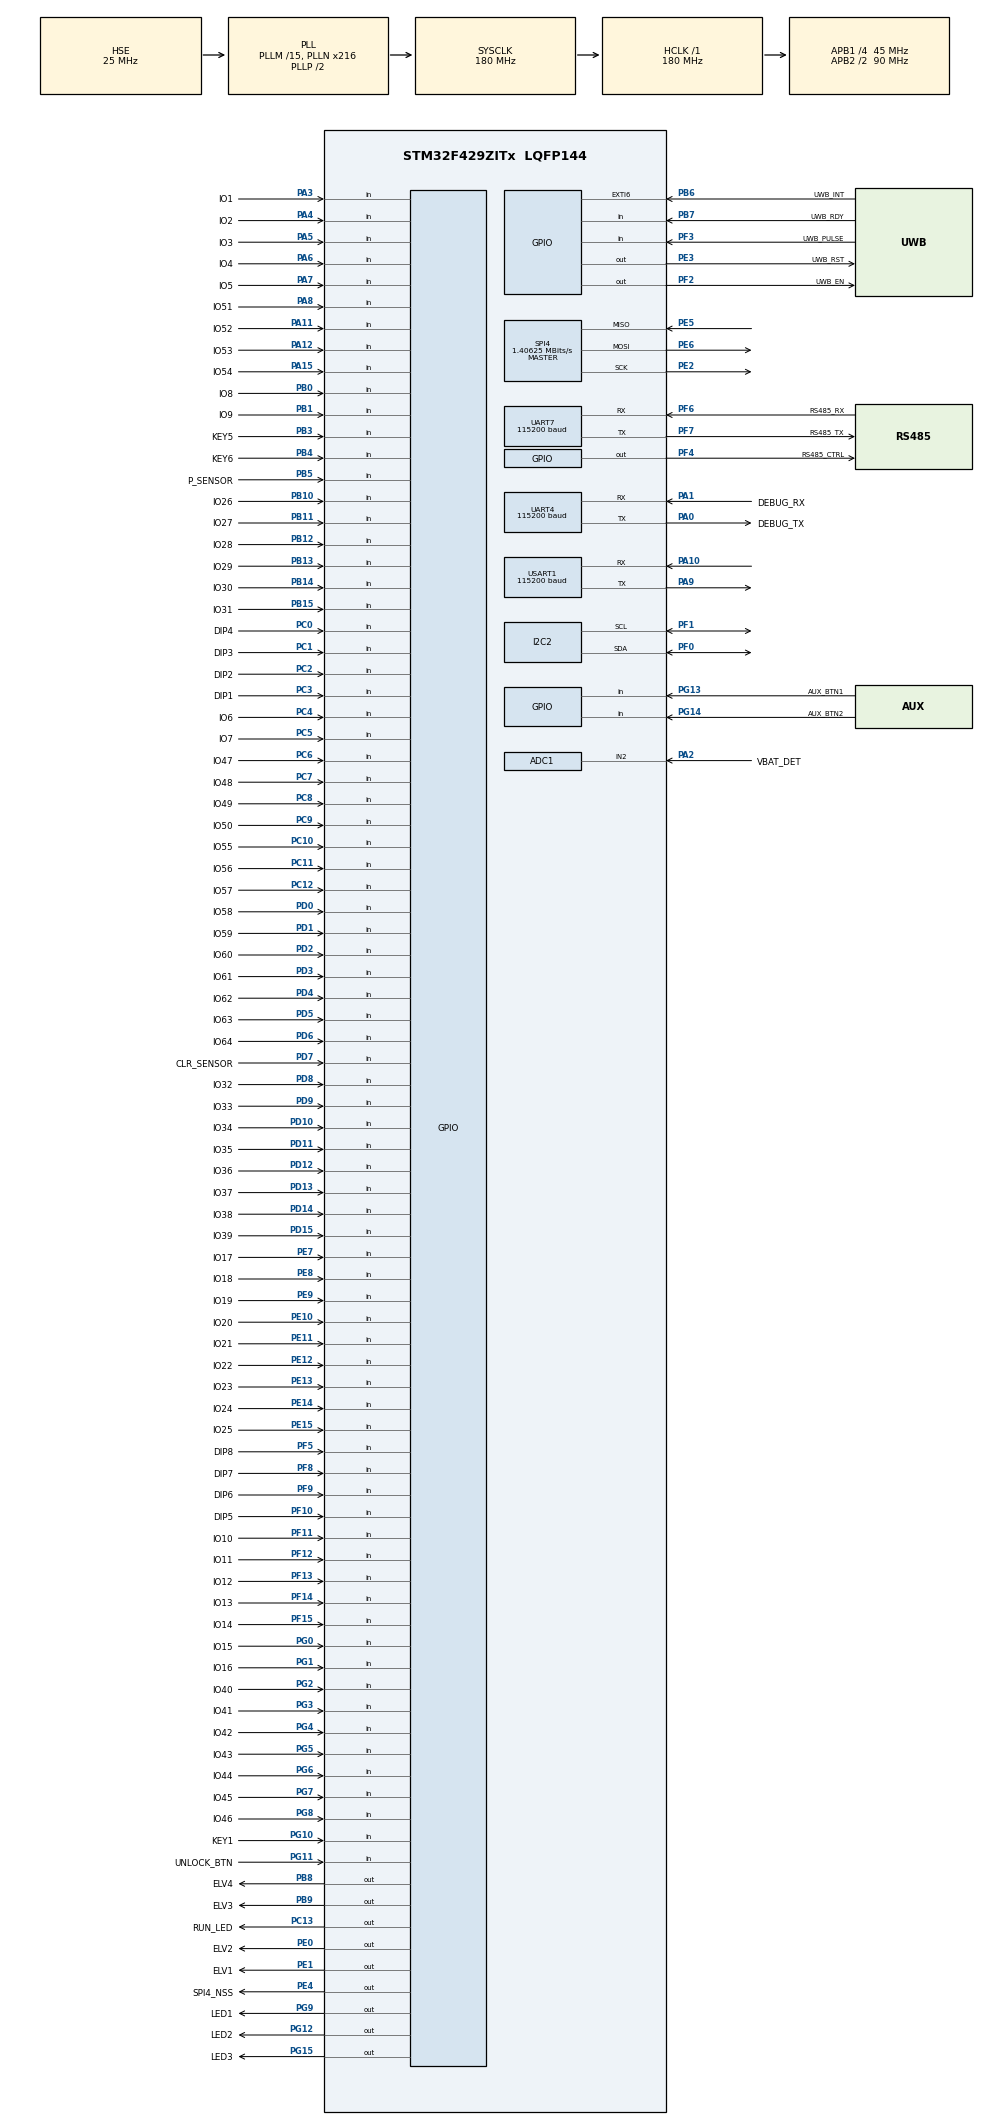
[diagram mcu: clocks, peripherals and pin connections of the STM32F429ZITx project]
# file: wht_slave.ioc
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ADC1.Channel-0\#ChannelRegularConversion=ADC_CHANNEL_2
ADC1.NbrOfConversion=1
ADC1.NbrOfConversionFlag=1
ADC1.Rank-0\#ChannelRegularConversion=1
ADC1.SamplingTime-0\#ChannelRegularConversion=ADC_SAMPLETIME_144CYCLES
ADC1.master=1
Dma.Request0=UART4_TX
Dma.Request1=UART7_TX
Dma.UART4_TX.0.Direction=DMA_MEMORY_TO_PERIPH
Dma.UART4_TX.0.FIFOMode=DMA_FIFOMODE_DISABLE
Dma.UART4_TX.0.Instance=DMA1_Stream4
Dma.UART4_TX.0.MemDataAlignment=DMA_MDATAALIGN_BYTE
Dma.UART4_TX.0.MemInc=DMA_MINC_ENABLE
Dma.UART4_TX.0.Mode=DMA_NORMAL
Dma.UART4_TX.0.PeriphDataAlignment=DMA_PDATAALIGN_BYTE
Dma.UART4_TX.0.PeriphInc=DMA_PINC_DISABLE
Dma.UART4_TX.0.Priority=DMA_PRIORITY_LOW
Dma.UART7_TX.1.Direction=DMA_MEMORY_TO_PERIPH
Dma.UART7_TX.1.FIFOMode=DMA_FIFOMODE_DISABLE
Dma.UART7_TX.1.Instance=DMA1_Stream1
Dma.UART7_TX.1.MemDataAlignment=DMA_MDATAALIGN_BYTE
Dma.UART7_TX.1.MemInc=DMA_MINC_ENABLE
Dma.UART7_TX.1.Mode=DMA_NORMAL
Dma.UART7_TX.1.PeriphDataAlignment=DMA_PDATAALIGN_BYTE
Dma.UART7_TX.1.PeriphInc=DMA_PINC_DISABLE
Dma.UART7_TX.1.Priority=DMA_PRIORITY_LOW
FREERTOS.Tasks01=defaultTask,24,1024,StartDefaultTask,Default,NULL,Dynamic,NULL,NULL
FREERTOS.configTOTAL_HEAP_SIZE=153600
Mcu.Family=STM32F4
Mcu.Name=STM32F429ZITx
Mcu.Package=LQFP144
NVIC.DMA1_Stream1_IRQn=true\:5\:0\:false\:false\:true\:true\:false\:true\:true
NVIC.DMA1_Stream4_IRQn=true\:5\:0\:false\:false\:true\:true\:false\:true\:true
NVIC.EXTI9_5_IRQn=true\:5\:0\:true\:false\:true\:true\:true\:true\:true
NVIC.PriorityGroup=NVIC_PRIORITYGROUP_4
NVIC.TIM6_DAC_IRQn=true\:15\:0\:false\:false\:true\:false\:false\:true\:true
NVIC.TimeBase=TIM6_DAC_IRQn
NVIC.TimeBaseIP=TIM6
NVIC.UART4_IRQn=true\:7\:0\:true\:false\:true\:true\:true\:true\:true
NVIC.UART7_IRQn=true\:7\:0\:true\:false\:true\:true\:true\:true\:true
PA0/WKUP.GPIO_Label=DEBUG_TX
PA0/WKUP.Mode=Asynchronous
PA0/WKUP.Signal=UART4_TX
PA1.GPIO_Label=DEBUG_RX
PA1.Mode=Asynchronous
PA1.Signal=UART4_RX
PA10.Mode=Asynchronous
PA10.Signal=USART1_RX
PA11.GPIO_Label=IO52
PA11.Signal=GPIO_Input
PA12.GPIO_Label=IO53
PA12.Signal=GPIO_Input
PA13.Signal=SYS_JTMS-SWDIO
PA14.Signal=SYS_JTCK-SWCLK
PA15.GPIO_Label=IO54
PA15.Signal=GPIO_Input
PA2.GPIO_Label=VBAT_DET
PA2.Signal=SharedAnalog_PA2
PA3.GPIO_Label=IO1
PA3.Signal=GPIO_Input
PA4.GPIO_Label=IO2
PA4.Signal=GPIO_Input
PA5.GPIO_Label=IO3
PA5.Signal=GPIO_Input
PA6.GPIO_Label=IO4
PA6.Signal=GPIO_Input
PA7.GPIO_Label=IO5
PA7.Signal=GPIO_Input
PA8.GPIO_Label=IO51
PA8.Signal=GPIO_Input
PA9.Mode=Asynchronous
PA9.Signal=USART1_TX
PB0.GPIO_Label=IO8
PB0.Signal=GPIO_Input
PB1.GPIO_Label=IO9
PB1.Signal=GPIO_Input
PB10.GPIO_Label=IO26
PB10.Signal=GPIO_Input
PB11.GPIO_Label=IO27
PB11.Signal=GPIO_Input
PB12.GPIO_Label=IO28
PB12.Signal=GPIO_Input
PB13.GPIO_Label=IO29
PB13.Signal=GPIO_Input
PB14.GPIO_Label=IO30
PB14.Signal=GPIO_Input
PB15.GPIO_Label=IO31
PB15.Signal=GPIO_Input
PB3.GPIO_Label=KEY5
PB3.Signal=GPIO_Input
PB4.GPIO_Label=KEY6
PB4.Signal=GPIO_Input
PB5.GPIO_Label=P_SENSOR
PB5.Signal=GPIO_Input
PB6.GPIO_Label=UWB_INT
PB6.GPIO_ModeDefaultEXTI=GPIO_MODE_IT_FALLING
PB6.Signal=GPXTI6
PB7.GPIO_Label=UWB_RDY
PB7.Signal=GPIO_Input
PB8.GPIO_Label=ELV4
PB8.Signal=GPIO_Output
PB9.GPIO_Label=ELV3
PB9.Signal=GPIO_Output
PC0.GPIO_Label=DIP4
PC0.Signal=GPIO_Input
PC1.GPIO_Label=DIP3
PC1.Signal=GPIO_Input
PC10.GPIO_Label=IO55
PC10.Signal=GPIO_Input
PC11.GPIO_Label=IO56
PC11.Signal=GPIO_Input
PC12.GPIO_Label=IO57
PC12.Signal=GPIO_Input
PC13.GPIO_Label=RUN_LED
PC13.PinState=GPIO_PIN_RESET
PC13.Signal=GPIO_Output
PC14/OSC32_IN.Signal=RCC_OSC32_IN
PC15/OSC32_OUT.Signal=RCC_OSC32_OUT
PC2.GPIO_Label=DIP2
PC2.Signal=GPIO_Input
PC3.GPIO_Label=DIP1
PC3.Signal=GPIO_Input
PC4.GPIO_Label=IO6
PC4.Signal=GPIO_Input
PC5.GPIO_Label=IO7
PC5.Signal=GPIO_Input
PC6.GPIO_Label=IO47
PC6.Signal=GPIO_Input
PC7.GPIO_Label=IO48
PC7.Signal=GPIO_Input
PC8.GPIO_Label=IO49
PC8.Signal=GPIO_Input
PC9.GPIO_Label=IO50
PC9.Signal=GPIO_Input
PD0.GPIO_Label=IO58
PD0.Signal=GPIO_Input
PD1.GPIO_Label=IO59
PD1.Signal=GPIO_Input
PD10.GPIO_Label=IO34
PD10.Signal=GPIO_Input
PD11.GPIO_Label=IO35
PD11.Signal=GPIO_Input
PD12.GPIO_Label=IO36
PD12.Signal=GPIO_Input
PD13.GPIO_Label=IO37
PD13.Signal=GPIO_Input
PD14.GPIO_Label=IO38
PD14.Signal=GPIO_Input
PD15.GPIO_Label=IO39
PD15.Signal=GPIO_Input
PD2.GPIO_Label=IO60
PD2.Signal=GPIO_Input
PD3.GPIO_Label=IO61
PD3.Signal=GPIO_Input
PD4.GPIO_Label=IO62
PD4.Signal=GPIO_Input
PD5.GPIO_Label=IO63
PD5.Signal=GPIO_Input
PD6.GPIO_Label=IO64
PD6.Signal=GPIO_Input
PD7.GPIO_Label=CLR_SENSOR
PD7.Signal=GPIO_Input
PD8.GPIO_Label=IO32
PD8.Signal=GPIO_Input
PD9.GPIO_Label=IO33
PD9.Signal=GPIO_Input
PE0.GPIO_Label=ELV2
PE0.Signal=GPIO_Output
PE1.GPIO_Label=ELV1
PE1.Signal=GPIO_Output
PE10.GPIO_Label=IO20
PE10.Signal=GPIO_Input
PE11.GPIO_Label=IO21
PE11.Signal=GPIO_Input
PE12.GPIO_Label=IO22
PE12.Signal=GPIO_Input
PE13.GPIO_Label=IO23
PE13.Signal=GPIO_Input
PE14.GPIO_Label=IO24
PE14.Signal=GPIO_Input
PE15.GPIO_Label=IO25
PE15.Signal=GPIO_Input
PE2.Mode=Full_Duplex_Master
PE2.Signal=SPI4_SCK
PE3.GPIO_Label=UWB_RST
PE3.GPIO_Speed=GPIO_SPEED_FREQ_VERY_HIGH
PE3.PinState=GPIO_PIN_SET
PE3.Signal=GPIO_Output
PE4.GPIO_Label=SPI4_NSS
PE4.GPIO_Speed=GPIO_SPEED_FREQ_VERY_HIGH
PE4.PinState=GPIO_PIN_SET
PE4.Signal=GPIO_Output
PE5.Mode=Full_Duplex_Master
PE5.Signal=SPI4_MISO
PE6.Mode=Full_Duplex_Master
PE6.Signal=SPI4_MOSI
PE7.GPIO_Label=IO17
PE7.Signal=GPIO_Input
PE8.GPIO_Label=IO18
PE8.Signal=GPIO_Input
PE9.GPIO_Label=IO19
PE9.Signal=GPIO_Input
PF0.Mode=I2C
PF0.Signal=I2C2_SDA
PF1.Mode=I2C
PF1.Signal=I2C2_SCL
PF10.GPIO_Label=DIP5
PF10.Signal=GPIO_Input
PF11.GPIO_Label=IO10
PF11.Signal=GPIO_Input
PF12.GPIO_Label=IO11
PF12.Signal=GPIO_Input
PF13.GPIO_Label=IO12
PF13.Signal=GPIO_Input
PF14.GPIO_Label=IO13
PF14.Signal=GPIO_Input
PF15.GPIO_Label=IO14
PF15.Signal=GPIO_Input
PF2.GPIO_Label=UWB_EN
PF2.GPIO_Speed=GPIO_SPEED_FREQ_VERY_HIGH
PF2.PinState=GPIO_PIN_SET
PF2.Signal=GPIO_Output
PF3.GPIO_Label=UWB_PULSE
PF3.Signal=GPIO_Input
PF4.GPIO_Label=RS485_CTRL
PF4.GPIO_Speed=GPIO_SPEED_FREQ_VERY_HIGH
PF4.Signal=GPIO_Output
PF5.GPIO_Label=DIP8
PF5.Signal=GPIO_Input
PF6.GPIO_Label=RS485_RX
PF6.Mode=Asynchronous
PF6.Signal=UART7_RX
PF7.GPIO_Label=RS485_TX
PF7.Mode=Asynchronous
PF7.Signal=UART7_TX
PF8.GPIO_Label=DIP7
PF8.Signal=GPIO_Input
PF9.GPIO_Label=DIP6
PF9.Signal=GPIO_Input
PG0.GPIO_Label=IO15
PG0.Signal=GPIO_Input
PG1.GPIO_Label=IO16
PG1.Signal=GPIO_Input
PG10.GPIO_Label=KEY1
PG10.Signal=GPIO_Input
PG11.GPIO_Label=UNLOCK_BTN
PG11.Signal=GPIO_Input
PG12.GPIO_Label=LED2
PG12.Signal=GPIO_Output
PG13.GPIO_Label=AUX_BTN1
PG13.Signal=GPIO_Input
PG14.GPIO_Label=AUX_BTN2
PG14.Signal=GPIO_Input
PG15.GPIO_Label=LED3
PG15.Signal=GPIO_Output
PG2.GPIO_Label=IO40
PG2.Signal=GPIO_Input
PG3.GPIO_Label=IO41
PG3.Signal=GPIO_Input
PG4.GPIO_Label=IO42
PG4.Signal=GPIO_Input
PG5.GPIO_Label=IO43
PG5.Signal=GPIO_Input
PG6.GPIO_Label=IO44
PG6.Signal=GPIO_Input
PG7.GPIO_Label=IO45
PG7.Signal=GPIO_Input
PG8.GPIO_Label=IO46
PG8.Signal=GPIO_Input
PG9.GPIO_Label=LED1
PG9.Signal=GPIO_Output
PH0/OSC_IN.Mode=HSE-External-Oscillator
PH0/OSC_IN.Signal=RCC_OSC_IN
PH1/OSC_OUT.Mode=HSE-External-Oscillator
PH1/OSC_OUT.Signal=RCC_OSC_OUT
ProjectManager.HeapSize=0x200
ProjectManager.StackSize=0x400
ProjectManager.TargetToolchain=CMake
RCC.48MHZClocksFreq_Value=90000000
RCC.AHBFreq_Value=180000000
RCC.APB1CLKDivider=RCC_HCLK_DIV4
RCC.APB1Freq_Value=45000000
RCC.APB1TimFreq_Value=90000000
RCC.APB2CLKDivider=RCC_HCLK_DIV2
RCC.APB2Freq_Value=90000000
RCC.APB2TimFreq_Value=180000000
RCC.CortexFreq_Value=180000000
RCC.HCLKFreq_Value=180000000
RCC.HSE_VALUE=25000000
RCC.HSI_VALUE=16000000
RCC.LSE_VALUE=32768
RCC.PLLM=15
RCC.PLLN=216
RCC.PLLSourceVirtual=RCC_PLLSOURCE_HSE
RCC.SYSCLKFreq_VALUE=180000000
RCC.SYSCLKSource=RCC_SYSCLKSOURCE_PLLCLK
RCC.VCOOutputFreq_Value=360000000
SH.SharedAnalog_PA2.0=GPIO_Analog
SH.SharedAnalog_PA2.1=ADC1_IN2,IN2
SPI4.BaudRatePrescaler=SPI_BAUDRATEPRESCALER_64
SPI4.CalculateBaudRate=1.40625 MBits/s
SPI4.Direction=SPI_DIRECTION_2LINES
SPI4.Mode=SPI_MODE_MASTER
SPI4.VirtualType=VM_MASTER
TIM2.AutoReloadPreload=TIM_AUTORELOAD_PRELOAD_ENABLE
TIM2.Period=0xFFFFFFFF
TIM2.Prescaler=89
UART4.BaudRate=115200
UART4.VirtualMode=Asynchronous
UART7.BaudRate=115200
UART7.VirtualMode=Asynchronous
USART1.BaudRate=115200
USART1.VirtualMode=VM_ASYNC
VP_FREERTOS_VS_CMSIS_V2.Mode=CMSIS_V2
VP_SYS_VS_tim6.Mode=TIM6
VP_TIM2_VS_ClockSourceINT.Mode=Internal
board=custom

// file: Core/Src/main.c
/* USER CODE BEGIN Header */
/**
 ******************************************************************************
 * @file           : main.c
 * @brief          : Main program body
 ******************************************************************************
 * @attention
 *
 * Copyright (c) 2025 STMicroelectronics.
 * All rights reserved.
 *
 * This software is licensed under terms that can be found in the LICENSE file
 * in the root directory of this software component.
 * If no LICENSE file comes with this software, it is provided AS-IS.
 *
 ******************************************************************************
 */
/* USER CODE END Header */
#include "main.h"
#include "cmsis_os.h"
#include "adc.h"
#include "dma.h"
#include "i2c.h"
#include "spi.h"
#include "tim.h"
#include "usart.h"
#include "gpio.h"

/* USER CODE BEGIN Includes */
#include <stdio.h>

#include "bootloader_flag.h"
#include "cmsis_os2.h"
#include "elog.h"
#include "factory_test.h"
#include "uart_cmd_handler.h"
/* USER CODE END Includes */

void SystemClock_Config(void);
void MX_FREERTOS_Init(void);

/* USER CODE BEGIN 0 */
void HAL_UART_TxCpltCallback(UART_HandleTypeDef *huart) {
    if (huart->Instance == RS485_UART.Instance) {
        extern osSemaphoreId_t elog_dma_lockHandle;
        osSemaphoreRelease(elog_dma_lockHandle);
        RS485_RX_EN(); // 传输完成后切换回接收模式
    }
}
/* USER CODE END 0 */

int main(void)
{

  /* USER CODE BEGIN 1 */
    SCB->VTOR = 0x08008000;
  /* USER CODE END 1 */

  /* MCU Configuration--------------------------------------------------------*/

  /* Reset of all peripherals, Initializes the Flash interface and the Systick. */
  HAL_Init();

  /* Configure the system clock */
  SystemClock_Config();

  /* Initialize all configured peripherals */
  MX_GPIO_Init();
  MX_DMA_Init();
  MX_UART4_Init();
  MX_SPI4_Init();
  MX_TIM2_Init();
  MX_I2C2_Init();
  MX_UART7_Init();
  MX_USART1_UART_Init();
  MX_ADC1_Init();
  /* USER CODE BEGIN 2 */

    elog_init();

    elog_set_fmt(ELOG_LVL_ASSERT, ELOG_FMT_ALL & ~ELOG_FMT_P_INFO);
    elog_set_fmt(ELOG_LVL_ERROR, ELOG_FMT_LVL | ELOG_FMT_TAG | ELOG_FMT_TIME);
    elog_set_fmt(ELOG_LVL_WARN, ELOG_FMT_LVL | ELOG_FMT_TAG | ELOG_FMT_TIME);
    elog_set_fmt(ELOG_LVL_INFO, ELOG_FMT_LVL | ELOG_FMT_TAG | ELOG_FMT_TIME);
    elog_set_fmt(ELOG_LVL_DEBUG,
                 ELOG_FMT_ALL & ~(ELOG_FMT_FUNC | ELOG_FMT_P_INFO));
    elog_set_fmt(ELOG_LVL_VERBOSE,
                 ELOG_FMT_ALL & ~(ELOG_FMT_FUNC | ELOG_FMT_P_INFO));
    elog_start();

    if (HAL_GPIO_ReadPin(DIP8_GPIO_Port, DIP8_Pin) == GPIO_PIN_RESET) {
        // If DIP8 is low, disable elog
        elog_set_output_enabled(false);
    }

    HAL_TIM_Base_Start(&htim2);

    // 初始化并检查bootloader标志位（这里只是检查，清除操作应该在bootloader中进行）
    if (check_bootloader_upgrade_flag()) {
        printf(
            "Bootloader upgrade flag detected but not cleared by "
            "bootloader!\r\n");
    }

    // 初始化工厂测试模式
    factory_test_init();
    // 初始化UART命令处理系统
    uart_cmd_handler_init();

  /* USER CODE END 2 */

  /* Init scheduler */
  osKernelInitialize();  /* Call init function for freertos objects (in cmsis_os2.c) */
  MX_FREERTOS_Init();

  /* Start scheduler */
  osKernelStart();

  /* We should never get here as control is now taken by the scheduler */

  /* Infinite loop */
    while (1) {

    }
}

void SystemClock_Config(void)
{
  RCC_OscInitTypeDef RCC_OscInitStruct = {0};
  RCC_ClkInitTypeDef RCC_ClkInitStruct = {0};

  /** Configure the main internal regulator output voltage
  */
  __HAL_RCC_PWR_CLK_ENABLE();
  __HAL_PWR_VOLTAGESCALING_CONFIG(PWR_REGULATOR_VOLTAGE_SCALE1);

  /** Initializes the RCC Oscillators according to the specified parameters
  * in the RCC_OscInitTypeDef structure.
  */
  RCC_OscInitStruct.OscillatorType = RCC_OSCILLATORTYPE_HSE;
  RCC_OscInitStruct.HSEState = RCC_HSE_ON;
  RCC_OscInitStruct.PLL.PLLState = RCC_PLL_ON;
  RCC_OscInitStruct.PLL.PLLSource = RCC_PLLSOURCE_HSE;
  RCC_OscInitStruct.PLL.PLLM = 15;
  RCC_OscInitStruct.PLL.PLLN = 216;
  RCC_OscInitStruct.PLL.PLLP = RCC_PLLP_DIV2;
  RCC_OscInitStruct.PLL.PLLQ = 4;
  if (HAL_RCC_OscConfig(&RCC_OscInitStruct) != HAL_OK)
  {
    Error_Handler();
  }

  /** Activate the Over-Drive mode
  */
  if (HAL_PWREx_EnableOverDrive() != HAL_OK)
  {
    Error_Handler();
  }

  /** Initializes the CPU, AHB and APB buses clocks
  */
  RCC_ClkInitStruct.ClockType = RCC_CLOCKTYPE_HCLK|RCC_CLOCKTYPE_SYSCLK
                              |RCC_CLOCKTYPE_PCLK1|RCC_CLOCKTYPE_PCLK2;
  RCC_ClkInitStruct.SYSCLKSource = RCC_SYSCLKSOURCE_PLLCLK;
  RCC_ClkInitStruct.AHBCLKDivider = RCC_SYSCLK_DIV1;
  RCC_ClkInitStruct.APB1CLKDivider = RCC_HCLK_DIV4;
  RCC_ClkInitStruct.APB2CLKDivider = RCC_HCLK_DIV2;

  if (HAL_RCC_ClockConfig(&RCC_ClkInitStruct, FLASH_LATENCY_5) != HAL_OK)
  {
    Error_Handler();
  }
}

void HAL_TIM_PeriodElapsedCallback(TIM_HandleTypeDef *htim)
{
  if (htim->Instance == TIM6)
  {
    HAL_IncTick();
  }
}

void Error_Handler(void)
{
  /* USER CODE BEGIN Error_Handler_Debug */
    /* User can add his own implementation to report the HAL error return state
     */
    __disable_irq();
    while (1) {
    }
  /* USER CODE END Error_Handler_Debug */
}
#ifdef USE_FULL_ASSERT
/**
  * @brief  Reports the name of the source file and the source line number
  *         where the assert_param error has occurred.
  * @param  file: pointer to the source file name
  * @param  line: assert_param error line source number
  * @retval None
  */
void assert_failed(uint8_t *file, uint32_t line)
{
  /* USER CODE BEGIN 6 */
    /* User can add his own implementation to report the file name and line
       number, ex: printf("Wrong parameters value: file %s on line %d\r\n",
       file, line) */
  /* USER CODE END 6 */
}
#endif /* USE_FULL_ASSERT */

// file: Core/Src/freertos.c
/* USER CODE BEGIN Header */
/**
 ******************************************************************************
 * File Name          : freertos.c
 * Description        : Code for freertos applications
 ******************************************************************************
 * @attention
 *
 * Copyright (c) 2025 STMicroelectronics.
 * All rights reserved.
 *
 * This software is licensed under terms that can be found in the LICENSE file
 * in the root directory of this software component.
 * If no LICENSE file comes with this software, it is provided AS-IS.
 *
 ******************************************************************************
 */
/* USER CODE END Header */

#include "FreeRTOS.h"
#include "task.h"
#include "main.h"
#include "cmsis_os.h"

/* USER CODE BEGIN Includes */
#include <stdio.h>

#include "elog.h"
#include "factory_test.h"
#include "gpio.h"
#include "uart_cmd_handler.h"
#include "usart.h"

/* USER CODE END Includes */

/* USER CODE BEGIN PTD */
typedef StaticTask_t osStaticThreadDef_t;
/* USER CODE END PTD */

/* Definitions for defaultTask */
osThreadId_t defaultTaskHandle;
const osThreadAttr_t defaultTask_attributes = {
  .name = "defaultTask",
  .stack_size = 2048 * 4, // 8KB stack size
  .priority = (osPriority_t) osPriorityNormal,
};

/* USER CODE BEGIN FunctionPrototypes */

/* Definitions for elog */
osThreadId_t elogHandle;
uint32_t elogBuffer[512];
osStaticThreadDef_t elogControlBlock;
const osThreadAttr_t elog_attributes = {
    .name = "elog",
    .stack_mem = &elogBuffer[0],
    .stack_size = sizeof(elogBuffer),
    .cb_mem = &elogControlBlock,
    .cb_size = sizeof(elogControlBlock),
    .priority = (osPriority_t)osPriorityLow,
};
/* Definitions for elog_lock */
osSemaphoreId_t elog_lockHandle;
const osSemaphoreAttr_t elog_lock_attributes = {.name = "elog_lock"};
/* Definitions for elog_async */
osSemaphoreId_t elog_asyncHandle;
const osSemaphoreAttr_t elog_async_attributes = {.name = "elog_async"};
/* Definitions for elog_dma_lock */
osSemaphoreId_t elog_dma_lockHandle;
const osSemaphoreAttr_t elog_dma_lock_attributes = {.name = "elog_dma_lock"};

extern int main_app(void);
extern void elog_entry(void *argument);
/* USER CODE END FunctionPrototypes */

void StartDefaultTask(void *argument);

void MX_FREERTOS_Init(void); /* (MISRA C 2004 rule 8.1) */

void MX_FREERTOS_Init(void) {

  /* USER CODE BEGIN RTOS_SEMAPHORES */
    /* add semaphores, ... */
    /* creation of elog_lock */
    elog_lockHandle = osSemaphoreNew(1, 1, &elog_lock_attributes);

    /* creation of elog_async */
    elog_asyncHandle = osSemaphoreNew(1, 1, &elog_async_attributes);

    /* creation of elog_dma_lock */
    elog_dma_lockHandle = osSemaphoreNew(1, 1, &elog_dma_lock_attributes);

  /* USER CODE END RTOS_SEMAPHORES */

  /* Create the thread(s) */
  /* creation of defaultTask */
  defaultTaskHandle = osThreadNew(StartDefaultTask, NULL, &defaultTask_attributes);

  /* USER CODE BEGIN RTOS_THREADS */
    /* add threads, ... */

    /* creation of elog */
    elogHandle = osThreadNew(elog_entry, NULL, &elog_attributes);

  /* USER CODE END RTOS_THREADS */

}

void StartDefaultTask(void *argument)
{
  /* USER CODE BEGIN StartDefaultTask */
    osDelay(50);    // 等待系统稳定

    // 阻塞式检测工厂测试入口指令（1秒）
    if (factory_test_blocking_check_entry()) {
        // 进入工厂测试模式
        factory_test_enter_mode();

        // 工厂测试模式下的主循环
        for (;;) {
            factory_test_task_process();
            osDelay(10);
        }
    } else {
        // 没有检测到工厂测试指令，进入正常应用程序

        // increase RS485 uart baudrate to 460800 for a better debug experience
        RS485_UART.Init.BaudRate = 460800;
        HAL_UART_Init(&RS485_UART);
        // 重新启动UART接收中断，因为波特率更改后中断会失效
        uart_cmd_handler_restart_interrupt();

        main_app();

        // 正常应用程序完成后的循环
        for (;;) {
            HAL_GPIO_TogglePin(GPIOC, GPIO_PIN_13);
            osDelay(500);
        }
    }
  /* USER CODE END StartDefaultTask */
}

/* USER CODE BEGIN Application */

int __io_putchar(int ch) {
    RS485_TX_EN();
    HAL_UART_Transmit(&RS485_UART, (uint8_t *)&ch, 1, HAL_MAX_DELAY);
    RS485_RX_EN();
    return ch;
}

/* USER CODE END Application */
